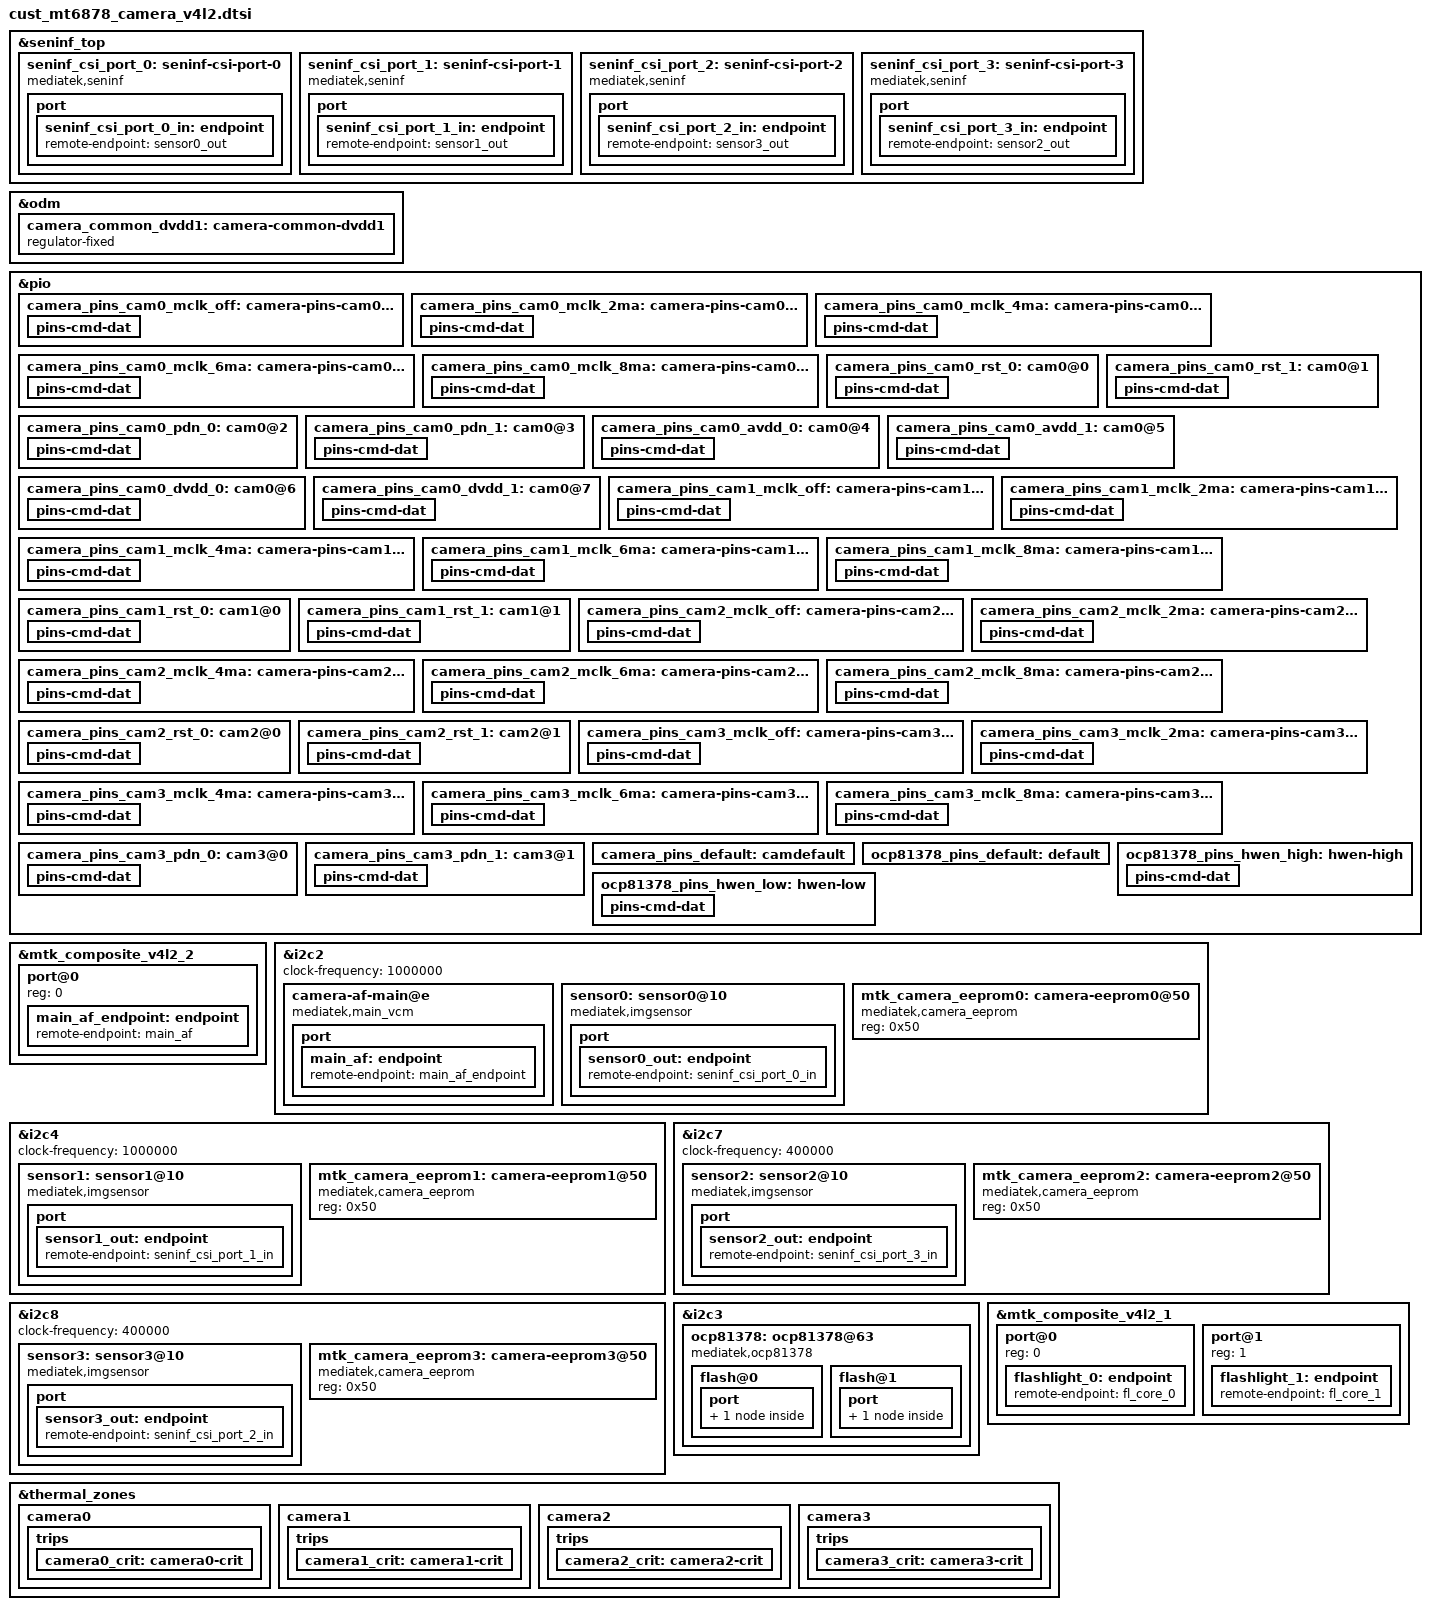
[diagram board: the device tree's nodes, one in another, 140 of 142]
// SPDX-License-Identifier: GPL-2.0
/* Copyright (c) 2020 MediaTek Inc. */
#include <dt-bindings/clock/mt6878-clk.h>

&seninf_top {
		seninf_csi_port_0: seninf-csi-port-0 {
			compatible = "mediatek,seninf";
			csi-port = "0";
			dphy-settle-delay-dt = <17>;
			nvmem-cells = <&csi_efuse0>;
			nvmem-cell-names = "rg_csi";
			port {
				seninf_csi_port_0_in: endpoint {
					remote-endpoint = <&sensor0_out>;
				};
			};
		};

		seninf_csi_port_1: seninf-csi-port-1 {
			compatible = "mediatek,seninf";
			csi-port = "1";
			hs-trail-parameter = <0x20>;
			nvmem-cells = <&csi_efuse1>;
			nvmem-cell-names = "rg_csi";
			port {
				seninf_csi_port_1_in: endpoint {
					remote-endpoint = <&sensor1_out>;
				};
			};
		};

		seninf_csi_port_2: seninf-csi-port-2 {
			compatible = "mediatek,seninf";
			csi-port = "2A";
			hs-trail-parameter = <0x20>;
			nvmem-cells = <&csi_efuse2>;
			nvmem-cell-names = "rg_csi";
			port {
				seninf_csi_port_2_in: endpoint {
					remote-endpoint = <&sensor3_out>;
				};
			};
		};
		seninf_csi_port_3: seninf-csi-port-3 {
			compatible = "mediatek,seninf";
			csi-port = "3A";
			nvmem-cells = <&csi_efuse3>;
			nvmem-cell-names = "rg_csi";
			port {
				seninf_csi_port_3_in: endpoint {
					remote-endpoint = <&sensor2_out>;
				};
			};
		};
};

/* CAMERA GPIO fixed to regulator */
&odm {
	camera_common_dvdd1: camera-common-dvdd1 {
		compatible = "regulator-fixed";
		regulator-name = "camera-common-dovdd";
		regulator-min-microvolt = <1200000>;
		regulator-max-microvolt = <1200000>;
		enable-active-high;
		gpio = <&pio 37 0x0>;
	};
};

/* CAMERA GPIO standardization */
&pio {
	camera_pins_cam0_mclk_off: camera-pins-cam0-mclk-off {
		pins-cmd-dat {
			pinmux = <PINMUX_GPIO92__FUNC_GPIO92>;
			drive-strength = <1>;
		};
	};
	camera_pins_cam0_mclk_2ma: camera-pins-cam0-mclk-2ma {
		pins-cmd-dat {
			pinmux = <PINMUX_GPIO92__FUNC_CMMCLK0>;
			drive-strength = <0>;
		};
	};
	camera_pins_cam0_mclk_4ma: camera-pins-cam0-mclk-4ma {
		pins-cmd-dat {
			pinmux = <PINMUX_GPIO92__FUNC_CMMCLK0>;
			drive-strength = <1>;
		};
	};
	camera_pins_cam0_mclk_6ma: camera-pins-cam0-mclk-6ma {
		pins-cmd-dat {
			pinmux = <PINMUX_GPIO92__FUNC_CMMCLK0>;
			drive-strength = <2>;
		};
	};
	camera_pins_cam0_mclk_8ma: camera-pins-cam0-mclk-8ma {
		pins-cmd-dat {
			pinmux = <PINMUX_GPIO92__FUNC_CMMCLK0>;
			drive-strength = <3>;
		};
	};
	camera_pins_cam0_rst_0: cam0@0 {
		pins-cmd-dat {
			pinmux = <PINMUX_GPIO24__FUNC_GPIO24>;
			slew-rate = <1>;
			output-low;
		};
	};
	camera_pins_cam0_rst_1: cam0@1 {
		pins-cmd-dat {
			pinmux = <PINMUX_GPIO24__FUNC_GPIO24>;
			slew-rate = <1>;
			output-high;
		};
	};
	camera_pins_cam0_pdn_0: cam0@2 {
		pins-cmd-dat {
			pinmux = <PINMUX_GPIO19__FUNC_GPIO19>;
			slew-rate = <1>;
			output-low;
		};
	};
	camera_pins_cam0_pdn_1: cam0@3 {
		pins-cmd-dat {
			pinmux = <PINMUX_GPIO19__FUNC_GPIO19>;
			slew-rate = <1>;
			output-high;
		};
	};
	camera_pins_cam0_avdd_0: cam0@4 {
		pins-cmd-dat {
			pinmux = <PINMUX_GPIO115__FUNC_GPIO115>;
			slew-rate = <1>;
			output-low;
		};
	};
	camera_pins_cam0_avdd_1: cam0@5 {
		pins-cmd-dat {
			pinmux = <PINMUX_GPIO115__FUNC_GPIO115>;
			slew-rate = <1>;
			output-high;
		};
	};
	camera_pins_cam0_dvdd_0: cam0@6 {
		pins-cmd-dat {
			pinmux = <PINMUX_GPIO36__FUNC_GPIO36>;
			slew-rate = <1>;
			output-low;
		};
	};
	camera_pins_cam0_dvdd_1: cam0@7 {
		pins-cmd-dat {
			pinmux = <PINMUX_GPIO36__FUNC_GPIO36>;
			slew-rate = <1>;
			output-high;
		};
	};

	camera_pins_cam1_mclk_off: camera-pins-cam1-mclk-off {
		pins-cmd-dat {
			pinmux = <PINMUX_GPIO93__FUNC_GPIO93>;
			drive-strength = <1>;
		};
	};
	camera_pins_cam1_mclk_2ma: camera-pins-cam1-mclk-2ma {
		pins-cmd-dat {
			pinmux = <PINMUX_GPIO93__FUNC_CMMCLK1>;
			drive-strength = <0>;
		};
	};
	camera_pins_cam1_mclk_4ma: camera-pins-cam1-mclk-4ma {
		pins-cmd-dat {
			pinmux = <PINMUX_GPIO93__FUNC_CMMCLK1>;
			drive-strength = <1>;
		};
	};
	camera_pins_cam1_mclk_6ma: camera-pins-cam1-mclk-6ma {
		pins-cmd-dat {
			pinmux = <PINMUX_GPIO93__FUNC_CMMCLK1>;
			drive-strength = <2>;
		};
	};
	camera_pins_cam1_mclk_8ma: camera-pins-cam1-mclk-8ma {
		pins-cmd-dat {
			pinmux = <PINMUX_GPIO93__FUNC_CMMCLK1>;
			drive-strength = <3>;
		};
	};
	camera_pins_cam1_rst_0: cam1@0 {
		pins-cmd-dat {
			pinmux = <PINMUX_GPIO25__FUNC_GPIO25>;
			slew-rate = <1>;
			output-low;
		};
	};
	camera_pins_cam1_rst_1: cam1@1 {
		pins-cmd-dat {
			pinmux = <PINMUX_GPIO25__FUNC_GPIO25>;
			slew-rate = <1>;
			output-high;
		};
	};

	camera_pins_cam2_mclk_off: camera-pins-cam2-mclk-off {
		pins-cmd-dat {
			pinmux = <PINMUX_GPIO95__FUNC_GPIO95>;
			drive-strength = <1>;
		};
	};
	camera_pins_cam2_mclk_2ma: camera-pins-cam2-mclk-2ma {
		pins-cmd-dat {
			pinmux = <PINMUX_GPIO95__FUNC_CMMCLK3>;
			drive-strength = <0>;
		};
	};
	camera_pins_cam2_mclk_4ma: camera-pins-cam2-mclk-4ma {
		pins-cmd-dat {
			pinmux = <PINMUX_GPIO95__FUNC_CMMCLK3>;
			drive-strength = <1>;
		};
	};
	camera_pins_cam2_mclk_6ma: camera-pins-cam2-mclk-6ma {
		pins-cmd-dat {
			pinmux = <PINMUX_GPIO95__FUNC_CMMCLK3>;
			drive-strength = <2>;
		};
	};
	camera_pins_cam2_mclk_8ma: camera-pins-cam2-mclk-8ma {
		pins-cmd-dat {
			pinmux = <PINMUX_GPIO95__FUNC_CMMCLK3>;
			drive-strength = <3>;
		};
	};
	camera_pins_cam2_rst_0: cam2@0 {
		pins-cmd-dat {
			pinmux = <PINMUX_GPIO27__FUNC_GPIO27>;
			slew-rate = <1>;
			output-low;
		};
	};
	camera_pins_cam2_rst_1: cam2@1 {
		pins-cmd-dat {
			pinmux = <PINMUX_GPIO27__FUNC_GPIO27>;
			slew-rate = <1>;
			output-high;
		};
	};

	camera_pins_cam3_mclk_off: camera-pins-cam3-mclk-off {
		pins-cmd-dat {
			pinmux = <PINMUX_GPIO94__FUNC_GPIO94>;
			drive-strength = <1>;
		};
	};
	camera_pins_cam3_mclk_2ma: camera-pins-cam3-mclk-2ma {
		pins-cmd-dat {
			pinmux = <PINMUX_GPIO94__FUNC_CMMCLK2>;
			drive-strength = <0>;
		};
	};
	camera_pins_cam3_mclk_4ma: camera-pins-cam3-mclk-4ma {
		pins-cmd-dat {
			pinmux = <PINMUX_GPIO94__FUNC_CMMCLK2>;
			drive-strength = <1>;
		};
	};
	camera_pins_cam3_mclk_6ma: camera-pins-cam3-mclk-6ma {
		pins-cmd-dat {
			pinmux = <PINMUX_GPIO94__FUNC_CMMCLK2>;
			drive-strength = <2>;
		};
	};
	camera_pins_cam3_mclk_8ma: camera-pins-cam3-mclk-8ma {
		pins-cmd-dat {
			pinmux = <PINMUX_GPIO94__FUNC_CMMCLK2>;
			drive-strength = <3>;
		};
	};
	camera_pins_cam3_pdn_0: cam3@0 {
		pins-cmd-dat {
			pinmux = <PINMUX_GPIO21__FUNC_GPIO21>;
			slew-rate = <1>;
			output-low;
		};
	};
	camera_pins_cam3_pdn_1: cam3@1 {
		pins-cmd-dat {
			pinmux = <PINMUX_GPIO21__FUNC_GPIO21>;
			slew-rate = <1>;
			output-high;
		};
	};
	camera_pins_default: camdefault {
	};
};
/* CAMERA GPIO end */

&mtk_composite_v4l2_2 {
	#address-cells = <1>;
	#size-cells = <0>;
	port@0 {
		reg = <0>;
		main_af_endpoint: endpoint {
			remote-endpoint = <&main_af>;
		};
	};
};

&i2c2 {
	status = "okay";
	clock-frequency = <1000000>;

	camera-af-main@e {
		compatible = "mediatek,main_vcm";
		reg = <0x0e>;
		vin-supply = <&wl28681_ldo7>;
		port {
			main_af: endpoint {
				remote-endpoint = <&main_af_endpoint>;
			};
		};
	};

	sensor0: sensor0@10 {
		compatible = "mediatek,imgsensor";
		sensor-names = "ov64b40_mipi_raw";
		reg = <0x10>;

		#thermal-sensor-cells = <0>;

		pinctrl-names = "mclk_off",
				"mclk_2mA",
				"mclk_4mA",
				"mclk_6mA",
				"mclk_8mA",
				"rst_low",
				"rst_high",
				"pdn_low",
				"pdn_high",
				"avdd_off",
				"avdd_on",
				"dvdd_off",
				"dvdd_on";

		pinctrl-0 = <&camera_pins_cam0_mclk_off>;
		pinctrl-1 = <&camera_pins_cam0_mclk_2ma>;
		pinctrl-2 = <&camera_pins_cam0_mclk_4ma>;
		pinctrl-3 = <&camera_pins_cam0_mclk_6ma>;
		pinctrl-4 = <&camera_pins_cam0_mclk_8ma>;
		pinctrl-5 = <&camera_pins_cam0_rst_0>;
		pinctrl-6 = <&camera_pins_cam0_rst_1>;
		pinctrl-7 = <&camera_pins_cam0_pdn_0>;
		pinctrl-8 = <&camera_pins_cam0_pdn_1>;
		pinctrl-9 = <&camera_pins_cam0_avdd_0>;
		pinctrl-10 = <&camera_pins_cam0_avdd_1>;
		pinctrl-11 = <&camera_pins_cam0_dvdd_0>;
		pinctrl-12 = <&camera_pins_cam0_dvdd_1>;

		dovdd-supply = <&wl28681_ldo6>;
		dvdd1-supply = <&camera_common_dvdd1>;

		clocks = <&topckgen_clk CLK_TOP_UVPLL192M_D32>,
			<&topckgen_clk CLK_TOP_UVPLL192M_D16>,
			<&topckgen_clk CLK_TOP_OSC_D20>,
			<&topckgen_clk CLK_TOP_UVPLL192M_D10>,
			<&topckgen_clk CLK_TOP_UVPLL192M_D8>,
			<&topckgen_clk CLK_TOP_TCK_26M_MX9>,
			<&topckgen_clk CLK_TOP_UNIVPLL_D6_D8>,
			<&topckgen_clk CLK_TOP_CAMTG_SEL>;
		clock-names = "6", "12", "13", "19.2", "24", "26", "52", "mclk";


		status = "okay";
		port {
			sensor0_out: endpoint {
				remote-endpoint = <&seninf_csi_port_0_in>;
			};
		};
	};

	mtk_camera_eeprom0:camera-eeprom0@50 {
		compatible = "mediatek,camera_eeprom";
		reg = <0x50>;
		status = "okay";
	};
};

&i2c4 {
	status = "okay";
	clock-frequency = <1000000>;

	sensor1: sensor1@10 {
		compatible = "mediatek,imgsensor";
		sensor-names = "gc32e1sub_mipi_raw";
		reg = <0x10>;

		#thermal-sensor-cells = <0>;

		pinctrl-names = "mclk_off",
				"mclk_2mA",
				"mclk_4mA",
				"mclk_6mA",
				"mclk_8mA",
				"rst_low",
				"rst_high";

		pinctrl-0 = <&camera_pins_cam1_mclk_off>;
		pinctrl-1 = <&camera_pins_cam1_mclk_2ma>;
		pinctrl-2 = <&camera_pins_cam1_mclk_4ma>;
		pinctrl-3 = <&camera_pins_cam1_mclk_6ma>;
		pinctrl-4 = <&camera_pins_cam1_mclk_8ma>;
		pinctrl-5 = <&camera_pins_cam1_rst_0>;
		pinctrl-6 = <&camera_pins_cam1_rst_1>;

		dvdd-supply = <&wl28681_ldo1>;
		avdd-supply = <&wl28681_ldo3>;
		dovdd-supply = <&wl28681_ldo6>;
		dvdd1-supply = <&camera_common_dvdd1>;

		clocks = <&topckgen_clk CLK_TOP_UVPLL192M_D32>,
			<&topckgen_clk CLK_TOP_UVPLL192M_D16>,
			<&topckgen_clk CLK_TOP_OSC_D20>,
			<&topckgen_clk CLK_TOP_UVPLL192M_D10>,
			<&topckgen_clk CLK_TOP_UVPLL192M_D8>,
			<&topckgen_clk CLK_TOP_TCK_26M_MX9>,
			<&topckgen_clk CLK_TOP_UNIVPLL_D6_D8>,
			<&topckgen_clk CLK_TOP_CAMTG2_SEL>;
		clock-names = "6", "12", "13", "19.2", "24", "26", "52", "mclk";

		status = "okay";
		port {
			sensor1_out: endpoint {
				remote-endpoint = <&seninf_csi_port_1_in>;
			};
		};
	};

	mtk_camera_eeprom1:camera-eeprom1@50 {
		compatible = "mediatek,camera_eeprom";
		reg = <0x50>;
		status = "okay";
	};
};


&i2c7 {
	status = "okay";
	clock-frequency = <400000>;

	sensor2: sensor2@10 {
		compatible = "mediatek,imgsensor";
		sensor-names = "gc08a3_mipi_raw";
		reg = <0x10>;
		reindex-to = <0>;

		cust-aov-csi-clk = <312>;

		pinctrl-names = "mclk_off",
				"mclk_2mA",
				"mclk_4mA",
				"mclk_6mA",
				"mclk_8mA",
				"rst_low",
				"rst_high";

		pinctrl-0 = <&camera_pins_cam2_mclk_off>;
		pinctrl-1 = <&camera_pins_cam2_mclk_2ma>;
		pinctrl-2 = <&camera_pins_cam2_mclk_4ma>;
		pinctrl-3 = <&camera_pins_cam2_mclk_6ma>;
		pinctrl-4 = <&camera_pins_cam2_mclk_8ma>;
		pinctrl-5 = <&camera_pins_cam2_rst_0>;
		pinctrl-6 = <&camera_pins_cam2_rst_1>;

		avdd-supply = <&wl28681_ldo4>;
		dovdd-supply = <&wl28681_ldo6>;
		dvdd-supply = <&wl28681_ldo2>;
		dvdd1-supply = <&camera_common_dvdd1>;


		clocks = <&topckgen_clk CLK_TOP_UVPLL192M_D32>,
			<&topckgen_clk CLK_TOP_UVPLL192M_D16>,
			<&topckgen_clk CLK_TOP_OSC_D20>,
			<&topckgen_clk CLK_TOP_UVPLL192M_D10>,
			<&topckgen_clk CLK_TOP_UVPLL192M_D8>,
			<&topckgen_clk CLK_TOP_TCK_26M_MX9>,
			<&topckgen_clk CLK_TOP_UNIVPLL_D6_D8>,
			<&topckgen_clk CLK_TOP_CAMTG4_SEL>;
		clock-names = "6", "12", "13", "19.2", "24", "26", "52", "mclk";


		status = "okay";
		port {
			sensor2_out: endpoint {
				remote-endpoint = <&seninf_csi_port_3_in>;
			};
		};
	};

	mtk_camera_eeprom2:camera-eeprom2@50 {
		compatible = "mediatek,camera_eeprom";
		reg = <0x50>;
		status = "okay";
	};
};


&i2c8 {
	status = "okay";
	clock-frequency = <400000>;

	sensor3: sensor3@10 {
		compatible = "mediatek,imgsensor";
		sensor-names = "gc02m1macro_mipi_raw";
		reg = <0x10>;
		reindex-to = <0>;

		cust-aov-csi-clk = <312>;

		#thermal-sensor-cells = <0>;

		pinctrl-names = "mclk_off",
				"mclk_2mA",
				"mclk_4mA",
				"mclk_6mA",
				"mclk_8mA",
				"pdn_low",
				"pdn_high";

		pinctrl-0 = <&camera_pins_cam3_mclk_off>;
		pinctrl-1 = <&camera_pins_cam3_mclk_2ma>;
		pinctrl-2 = <&camera_pins_cam3_mclk_4ma>;
		pinctrl-3 = <&camera_pins_cam3_mclk_6ma>;
		pinctrl-4 = <&camera_pins_cam3_mclk_8ma>;
		pinctrl-5 = <&camera_pins_cam3_pdn_0>;
		pinctrl-6 = <&camera_pins_cam3_pdn_1>;

		avdd-supply = <&wl28681_ldo5>;
		dovdd-supply = <&wl28681_ldo6>;

		clocks = <&topckgen_clk CLK_TOP_UVPLL192M_D32>,
			<&topckgen_clk CLK_TOP_UVPLL192M_D16>,
			<&topckgen_clk CLK_TOP_OSC_D20>,
			<&topckgen_clk CLK_TOP_UVPLL192M_D10>,
			<&topckgen_clk CLK_TOP_UVPLL192M_D8>,
			<&topckgen_clk CLK_TOP_TCK_26M_MX9>,
			<&topckgen_clk CLK_TOP_UNIVPLL_D6_D8>,
			<&topckgen_clk CLK_TOP_CAMTG3_SEL>;
		clock-names = "6", "12", "13", "19.2", "24", "26", "52", "mclk";

		status = "okay";
		port {
			sensor3_out: endpoint {
				remote-endpoint = <&seninf_csi_port_2_in>;
			};
		};
	};

	mtk_camera_eeprom3:camera-eeprom3@50 {
		compatible = "mediatek,camera_eeprom";
		reg = <0x50>;
		status = "okay";
	};
};

&i2c3 {
	#address-cells = <1>;
	#size-cells = <0>;
	ocp81378:ocp81378@63 {
		compatible = "mediatek,ocp81378";
		#address-cells = <1>;
		#size-cells = <0>;
		reg = <0x63>;
		#cooling-cells = <2>;
		pinctrl-names = "default", "hwen-high", "hwen-low";
		pinctrl-0 = <&ocp81378_pins_default>;
		pinctrl-1 = <&ocp81378_pins_hwen_high>;
		pinctrl-2 = <&ocp81378_pins_hwen_low>;
		status = "okay";
		flash@0{
			reg = <0>;
			type = <0>;
			ct = <0>;
			part = <0>;
			port {
				fl_core_0: endpoint {
					remote-endpoint = <&flashlight_0>;
				};
			};
		};
		flash@1{
			reg = <1>;
			type = <0>;
			ct = <1>;
			part = <0>;
			port {
				fl_core_1: endpoint {
					remote-endpoint = <&flashlight_1>;
				};
			};
		};
	};
};

&pio {
	ocp81378_pins_default: default {
	};

	ocp81378_pins_hwen_high: hwen-high {
		pins-cmd-dat {
            pinmux = <PINMUX_GPIO39__FUNC_GPIO39>;
			slew-rate = <1>;
			output-high;
		};
	};

	ocp81378_pins_hwen_low: hwen-low {
		pins-cmd-dat {
            pinmux = <PINMUX_GPIO39__FUNC_GPIO39>;
			slew-rate = <1>;
			output-low;
		};
	};
};

&mtk_composite_v4l2_1 {
	#address-cells = <1>;
	#size-cells = <0>;
	port@0 {
		reg = <0>;
		flashlight_0: endpoint {
			remote-endpoint = <&fl_core_0>;
		};
	};
	port@1 {
		reg = <1>;
		flashlight_1: endpoint {
			remote-endpoint = <&fl_core_1>;
		};
	};
};

&thermal_zones {
	camera0: camera0 {
		polling-delay = <0>; /* milliseconds */
		polling-delay-passive = <0>; /* milliseconds */
		thermal-sensors = <&sensor0>;
		trips {
			camera0_crit: camera0-crit {
				temperature = <120000>;
				hysteresis = <2000>;
				type = "passive";
			};
		};
	};
	camera1: camera1 {
		polling-delay = <0>; /* milliseconds */
		polling-delay-passive = <0>; /* milliseconds */
		thermal-sensors = <&sensor1>;
		trips {
			camera1_crit: camera1-crit {
				temperature = <120000>;
				hysteresis = <2000>;
				type = "passive";
			};
		};
	};
	camera2: camera2 {
		polling-delay = <0>; /* milliseconds */
		polling-delay-passive = <0>; /* milliseconds */
		thermal-sensors = <&sensor2>;
		trips {
			camera2_crit: camera2-crit {
				temperature = <120000>;
				hysteresis = <2000>;
				type = "passive";
			};
		};
	};
	camera3: camera3 {
		polling-delay = <0>; /* milliseconds */
		polling-delay-passive = <0>; /* milliseconds */
		thermal-sensors = <&sensor3>;
		trips {
			camera3_crit: camera3-crit {
				temperature = <120000>;
				hysteresis = <2000>;
				type = "passive";
			};
		};
	};
};
